# MPY32_208.0 register map
Vendor: Texas Instruments
Peripheral module from a debugger description file (folder msp430).
Registers are 16-bit, access not given, no defined reset value unless marked. A register's access mark holds for its fields unless they carry their own. Offsets are as the file gives them; lines under a group give offsets from that group; [hi:lo] are bit positions; {n}, {i} and the like mark numbered series; 'fields as' and 'values as' point back to an identical list; <NAME> marks a mode.

## MPY32
0x00 MPY — 16-bit operand one multiply
0x02 MPYS — 16-bit operand one signed multiply
0x04 MAC — 16-bit operand one multiply accumulate
0x06 MACS — 16-bit operand one signed multiply accumulate
0x08 OP2 — 16-bit operand two
0x0A RESLO — 16x16-bit result low word
0x0C RESHI — 16x16-bit result high word
0x0E SUMEXT — 16x16-bit sum extension register
0x10 MPY32L — 32-bit operand 1 multiply low word
0x12 MPY32H — 32-bit operand 1 multiply high word
0x14 MPYS32L — 32-bit operand 1 signed multiply low word
0x16 MPYS32H — 32-bit operand 1 signed multiply high word
0x18 MAC32L — 32-bit operand 1 multiply accumulate low word
0x1A MAC32H — 32-bit operand 1 multiply accumulate high word
0x1C MACS32L — 32-bit operand 1 signed multiply accumulate low word
0x1E MACS32H rw — 32-bit operand 1 signed multiply accumulate high word
  [15:8] MACS32H
0x20 OP2L — 32-bit operand 2 low word
0x22 OP2H — 32-bit operand 2 high word
0x24 RES0 — 32x32-bit result 0 least significant word
0x26 RES1 — 32x32-bit result 1
0x28 RES2 — 32x32-bit result 2
0x2A RES3 — 32x32-bit result 3 most significant word
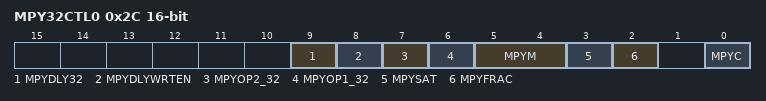
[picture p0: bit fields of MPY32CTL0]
0x2C MPY32CTL0 rw — MPY32 control register 0
  [9] MPYDLY32 — Delayed write mode.
    0=Writes are delayed until 64-bit result (RES0 to RES3) is available; 1=Writes are delayed until 32-bit result (RES0 to RES1) is available. 8 MPYDLYWRTEN
  [8] MPYDLYWRTEN — Delayed write enable.
    0=Writes are not delayed; 1=Writes are delayed
  [7] MPYOP2_32 — Multiplier bit width of operand 2
    0=16 bits; 1=32 bits
  [6] MPYOP1_32 — Multiplier bit width of operand 1
    0=16 bits; 1=32 bits
  [5:4] MPYM — Multiplier mode
    0=MPY (MPY Multiply); 1=MPYS (MPYS Signed multiply); 2=MAC (MAC Multiply accumulate); 3=MACS (MACS Signed multiply accumulate)
  [3] MPYSAT — Saturation mode
    0=DISABLE (Saturation mode disabled.); 1=ENABLE (Saturation mode enabled.)
  [2] MPYFRAC — Fractional mode.
    0=DISABLE (Fractional mode disabled.); 1=ENABLE (Fractional mode enabled.)
  [0] MPYC — Carry of the multiplier
    0=No carry for result; 1=Result has a carry
